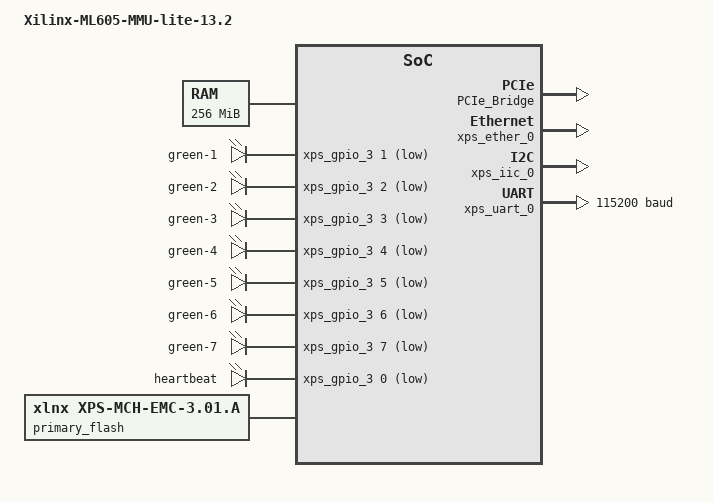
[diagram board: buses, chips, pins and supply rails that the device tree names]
/*
 * Device Tree Generator version: 1.02.a
 *
 * (C) Copyright 2007-2008 Xilinx, Inc.
 *
 * Based on original code:
 * (C) Copyright 2007-2011 PetaLogix Qld Pty Ltd
 *
 * (C) Copyright 2007-2010 Michal Simek
 * Michal SIMEK <monstr@monstr.eu>
 *
 * (C) Copyright 2010-2012 Li-Pro.Net
 * Stephan Linz <linz@li-pro.net>
 *
 * This program is free software; you can redistribute it and/or
 * modify it under the terms of the GNU General Public License as
 * published by the Free Software Foundation; either version 2 of
 * the License, or (at your option) any later version.
 *
 * This program is distributed in the hope that it will be useful,
 * but WITHOUT ANY WARRANTY; without even the implied warranty of
 * MERCHANTABILITY or FITNESS FOR A PARTICULAR PURPOSE. See the
 * GNU General Public License for more details.
 *
 * You should have received a copy of the GNU General Public License
 * along with this program; if not, write to the Free Software
 * Foundation, Inc., 59 Temple Place, Suite 330, Boston,
 * MA 02111-1307 USA
 *
 * CAUTION:  This file is automatically generated by libgen.
 * Version:  Xilinx EDK 13.2 EDK_O.61xd
 * Today is: Montag, the 12 of März, 2012; 08:22:30
 *
 * XPS project directory: Xilinx-ML605-MMU-lite-13.2
 */

/dts-v1/;
/ {
	#address-cells = <1>;
	#size-cells = <1>;
	compatible = "xlnx,microblaze";
	hard-reset-gpios = < &xps_gpio_0 0 1 >;
	model = "Xilinx-ML605-MMU-lite-13.2";
	aliases {
		ethernet0 = &xps_ether_0;
		serial0 = &xps_uart_0;
	} ;
	chosen {
		bootargs = "console=ttyUL0,115200 root=/dev/mtdblock2 rw rootfstype=jffs2 mtdparts=ae000000.flash:16384k(bpi),4096k(kernel),11776k(rootfs),384k(u-boot-xl)ro,128k(env) debug";
		linux,stdout-path = "/plb@0/serial@89ff0000";
	} ;
	cpus {
		#address-cells = <1>;
		#cpus = <0x1>;
		#size-cells = <0>;
		microblaze_0: cpu@0 {
			clock-frequency = <100000000>;
			compatible = "xlnx,microblaze-8.20.a";
			d-cache-baseaddr = <0x20000000>;
			d-cache-highaddr = <0x2fffffff>;
			d-cache-line-size = <0x10>;
			d-cache-size = <0x800>;
			device_type = "cpu";
			i-cache-baseaddr = <0x20000000>;
			i-cache-highaddr = <0x2fffffff>;
			i-cache-line-size = <0x10>;
			i-cache-size = <0x800>;
			model = "microblaze,8.20.a";
			reg = <0>;
			timebase-frequency = <100000000>;
			xlnx,addr-tag-bits = <0x11>;
			xlnx,allow-dcache-wr = <0x1>;
			xlnx,allow-icache-wr = <0x1>;
			xlnx,area-optimized = <0x0>;
			xlnx,avoid-primitives = <0x0>;
			xlnx,branch-target-cache-size = <0x0>;
			xlnx,cache-byte-size = <0x800>;
			xlnx,d-axi = <0x0>;
			xlnx,d-lmb = <0x1>;
			xlnx,d-plb = <0x1>;
			xlnx,data-size = <0x20>;
			xlnx,dcache-addr-tag = <0x11>;
			xlnx,dcache-always-used = <0x1>;
			xlnx,dcache-byte-size = <0x800>;
			xlnx,dcache-data-width = <0x0>;
			xlnx,dcache-force-tag-lutram = <0x0>;
			xlnx,dcache-interface = <0x0>;
			xlnx,dcache-line-len = <0x4>;
			xlnx,dcache-use-fsl = <0x1>;
			xlnx,dcache-use-writeback = <0x0>;
			xlnx,dcache-victims = <0x0>;
			xlnx,debug-enabled = <0x1>;
			xlnx,div-zero-exception = <0x0>;
			xlnx,dynamic-bus-sizing = <0x1>;
			xlnx,ecc-use-ce-exception = <0x0>;
			xlnx,edge-is-positive = <0x1>;
			xlnx,endianness = <0x0>;
			xlnx,family = "virtex6";
			xlnx,fault-tolerant = <0x0>;
			xlnx,fpu-exception = <0x0>;
			xlnx,freq = <0x5f5e100>;
			xlnx,fsl-data-size = <0x20>;
			xlnx,fsl-exception = <0x0>;
			xlnx,fsl-links = <0x0>;
			xlnx,i-axi = <0x0>;
			xlnx,i-lmb = <0x1>;
			xlnx,i-plb = <0x1>;
			xlnx,icache-always-used = <0x1>;
			xlnx,icache-data-width = <0x0>;
			xlnx,icache-force-tag-lutram = <0x0>;
			xlnx,icache-interface = <0x0>;
			xlnx,icache-line-len = <0x4>;
			xlnx,icache-streams = <0x0>;
			xlnx,icache-use-fsl = <0x1>;
			xlnx,icache-victims = <0x0>;
			xlnx,ill-opcode-exception = <0x1>;
			xlnx,instance = "microblaze_0";
			xlnx,interconnect = <0x1>;
			xlnx,interrupt-is-edge = <0x0>;
			xlnx,lockstep-slave = <0x0>;
			xlnx,mmu-dtlb-size = <0x4>;
			xlnx,mmu-itlb-size = <0x2>;
			xlnx,mmu-privileged-instr = <0x0>;
			xlnx,mmu-tlb-access = <0x3>;
			xlnx,mmu-zones = <0x2>;
			xlnx,number-of-pc-brk = <0x1>;
			xlnx,number-of-rd-addr-brk = <0x0>;
			xlnx,number-of-wr-addr-brk = <0x0>;
			xlnx,opcode-0x0-illegal = <0x1>;
			xlnx,optimization = <0x0>;
			xlnx,pvr = <0x2>;
			xlnx,pvr-user1 = <0x0>;
			xlnx,pvr-user2 = <0x0>;
			xlnx,reset-msr = <0x0>;
			xlnx,sco = <0x0>;
			xlnx,stream-interconnect = <0x0>;
			xlnx,unaligned-exceptions = <0x1>;
			xlnx,use-barrel = <0x1>;
			xlnx,use-branch-target-cache = <0x0>;
			xlnx,use-dcache = <0x1>;
			xlnx,use-div = <0x0>;
			xlnx,use-ext-brk = <0x1>;
			xlnx,use-ext-nm-brk = <0x1>;
			xlnx,use-extended-fsl-instr = <0x0>;
			xlnx,use-fpu = <0x0>;
			xlnx,use-hw-mul = <0x1>;
			xlnx,use-icache = <0x1>;
			xlnx,use-interrupt = <0x1>;
			xlnx,use-mmu = <0x3>;
			xlnx,use-msr-instr = <0x1>;
			xlnx,use-pcmp-instr = <0x1>;
			xlnx,use-stack-protection = <0x0>;
		} ;
	} ;
	mpmc_0: memory@20000000 {
		device_type = "memory";
		reg = < 0x20000000 0x10000000 >;
	} ;
	mb_plb: plb@0 {
		#address-cells = <1>;
		#size-cells = <1>;
		compatible = "xlnx,plb-v46-1.05.a", "xlnx,plb-v46-1.00.a", "simple-bus";
		ranges ;
		PCIe_Bridge: plbv46-pcie@8abf0000 {
			compatible = "xlnx,plbv46-pcie-4.07.a";
			interrupt-parent = <&xps_intc_0>;
			interrupts = < 5 2 >;
			reg = < 0x8abf0000 0x10000 >;
			xlnx,board = "none";
			xlnx,class-code = <0x58000>;
			xlnx,comp-timeout = <0x1>;
			xlnx,device = "6vlx240t";
			xlnx,device-id = <0x505>;
			xlnx,family = "virtex6";
			xlnx,include-baroffset-reg = <0x1>;
			xlnx,include-rc = <0x0>;
			xlnx,ipifbar-0 = <0xb0000000>;
			xlnx,ipifbar-1 = <0xe0000000>;
			xlnx,ipifbar-2 = <0xc0000000>;
			xlnx,ipifbar-3 = <0xffffffff>;
			xlnx,ipifbar-4 = <0xffffffff>;
			xlnx,ipifbar-5 = <0xffffffff>;
			xlnx,ipifbar-as-0 = <0x0>;
			xlnx,ipifbar-as-1 = <0x0>;
			xlnx,ipifbar-as-2 = <0x0>;
			xlnx,ipifbar-as-3 = <0x0>;
			xlnx,ipifbar-as-4 = <0x0>;
			xlnx,ipifbar-as-5 = <0x0>;
			xlnx,ipifbar-highaddr-0 = <0xb0ffffff>;
			xlnx,ipifbar-highaddr-1 = <0xffffffff>;
			xlnx,ipifbar-highaddr-2 = <0xcfffffff>;
			xlnx,ipifbar-highaddr-3 = <0x0>;
			xlnx,ipifbar-highaddr-4 = <0x0>;
			xlnx,ipifbar-highaddr-5 = <0x0>;
			xlnx,ipifbar-num = <0x3>;
			xlnx,ipifbar-space-type-0 = <0x1>;
			xlnx,ipifbar-space-type-1 = <0x1>;
			xlnx,ipifbar-space-type-2 = <0x1>;
			xlnx,ipifbar-space-type-3 = <0x1>;
			xlnx,ipifbar-space-type-4 = <0x1>;
			xlnx,ipifbar-space-type-5 = <0x1>;
			xlnx,ipifbar2pcibar-0 = <0x0>;
			xlnx,ipifbar2pcibar-1 = <0x0>;
			xlnx,ipifbar2pcibar-2 = <0xe0000000>;
			xlnx,ipifbar2pcibar-3 = <0xffffffff>;
			xlnx,ipifbar2pcibar-4 = <0xffffffff>;
			xlnx,ipifbar2pcibar-5 = <0xffffffff>;
			xlnx,mplb-awidth = <0x20>;
			xlnx,mplb-dwidth = <0x40>;
			xlnx,mplb-native-dwidth = <0x40>;
			xlnx,mplb-smallest-slave = <0x20>;
			xlnx,no-of-lanes = <0x1>;
			xlnx,pcibar-as = <0x1>;
			xlnx,pcibar-len-0 = <0x1c>;
			xlnx,pcibar-len-1 = <0x10>;
			xlnx,pcibar-len-2 = <0x10>;
			xlnx,pcibar-num = <0x1>;
			xlnx,pcibar2ipifbar-0 = <0xb0000000>;
			xlnx,pcibar2ipifbar-1 = <0xffffffff>;
			xlnx,pcibar2ipifbar-2 = <0xffffffff>;
			xlnx,pcie-cap-slot-implemented = <0x1>;
			xlnx,ref-clk-freq = <0x2>;
			xlnx,rev-id = <0x0>;
			xlnx,subfamily = "lx";
			xlnx,subsystem-id = <0x0>;
			xlnx,subsystem-vendor-id = <0x0>;
			xlnx,vendor-id = <0x10ee>;
		} ;
		gpio-leds {
			compatible = "gpio-leds";
			green-1 {
				gpios = < &xps_gpio_3 1 1 >;
				label = "green-1";
			} ;
			green-2 {
				gpios = < &xps_gpio_3 2 1 >;
				label = "green-2";
			} ;
			green-3 {
				gpios = < &xps_gpio_3 3 1 >;
				label = "green-3";
			} ;
			green-4 {
				gpios = < &xps_gpio_3 4 1 >;
				label = "green-4";
			} ;
			green-5 {
				gpios = < &xps_gpio_3 5 1 >;
				label = "green-5";
			} ;
			green-6 {
				gpios = < &xps_gpio_3 6 1 >;
				label = "green-6";
			} ;
			green-7 {
				gpios = < &xps_gpio_3 7 1 >;
				label = "green-7";
			} ;
			heartbeat {
				gpios = < &xps_gpio_3 0 1 >;
				label = "heartbeat";
				linux,default-trigger = "heartbeat";
			} ;
		} ;
		mbref_mio_0: uio@80400000 {
			compatible = "xlnx,plbv46-mbref-mio-1.00.a", "generic-uio";
			interrupt-parent = <&xps_intc_0>;
			interrupts = < 9 2 >;
			reg = < 0x80400000 0x10000 0x80410000 0x200 0x80411000 0x200 0x80412000 0x200 0x80413000 0x200 >;
			xlnx,family = "virtex6";
			xlnx,include-dphase-timer = <0x1>;
		} ;
		mbref_reg_0: uio@80800000 {
			compatible = "xlnx,plbv46-mbref-reg-1.00.a", "generic-uio";
			interrupt-parent = <&xps_intc_0>;
			interrupts = < 8 2 >;
			reg = < 0x80800000 0x10000 >;
			xlnx,family = "virtex6";
			xlnx,include-dphase-timer = <0x1>;
		} ;
		mdm_0: debug@8fff0000 {
			compatible = "xlnx,mdm-2.00.b", "xlnx,xps-uartlite-1.00.a";
			reg = < 0x8fff0000 0x10000 >;
			xlnx,family = "virtex6";
			xlnx,interconnect = <0x1>;
			xlnx,jtag-chain = <0x2>;
			xlnx,mb-dbg-ports = <0x1>;
			xlnx,use-uart = <0x1>;
		} ;
		mpmc@20000000 {
			#address-cells = <1>;
			#size-cells = <1>;
			compatible = "xlnx,mpmc-6.04.a";
			ranges ;
		} ;
		primary_flash: flash@ae000000 {
			bank-width = <2>;
			compatible = "xlnx,xps-mch-emc-3.01.a", "cfi-flash";
			reg = < 0xae000000 0x2000000 >;
			xlnx,family = "virtex6";
			xlnx,include-datawidth-matching-0 = <0x1>;
			xlnx,include-datawidth-matching-1 = <0x0>;
			xlnx,include-datawidth-matching-2 = <0x0>;
			xlnx,include-datawidth-matching-3 = <0x0>;
			xlnx,include-negedge-ioregs = <0x0>;
			xlnx,include-plb-ipif = <0x1>;
			xlnx,include-wrbuf = <0x1>;
			xlnx,max-mem-width = <0x10>;
			xlnx,mch-native-dwidth = <0x20>;
			xlnx,mch-splb-awidth = <0x20>;
			xlnx,mch-splb-clk-period-ps = <0x2710>;
			xlnx,mch0-accessbuf-depth = <0x10>;
			xlnx,mch0-protocol = <0x0>;
			xlnx,mch0-rddatabuf-depth = <0x10>;
			xlnx,mch1-accessbuf-depth = <0x10>;
			xlnx,mch1-protocol = <0x0>;
			xlnx,mch1-rddatabuf-depth = <0x10>;
			xlnx,mch2-accessbuf-depth = <0x10>;
			xlnx,mch2-protocol = <0x0>;
			xlnx,mch2-rddatabuf-depth = <0x10>;
			xlnx,mch3-accessbuf-depth = <0x10>;
			xlnx,mch3-protocol = <0x0>;
			xlnx,mch3-rddatabuf-depth = <0x10>;
			xlnx,mem0-width = <0x10>;
			xlnx,mem1-width = <0x20>;
			xlnx,mem2-width = <0x20>;
			xlnx,mem3-width = <0x20>;
			xlnx,num-banks-mem = <0x1>;
			xlnx,num-channels = <0x0>;
			xlnx,pagemode-flash-0 = <0x0>;
			xlnx,pagemode-flash-1 = <0x0>;
			xlnx,pagemode-flash-2 = <0x0>;
			xlnx,pagemode-flash-3 = <0x0>;
			xlnx,priority-mode = <0x0>;
			xlnx,synch-mem-0 = <0x0>;
			xlnx,synch-mem-1 = <0x0>;
			xlnx,synch-mem-2 = <0x0>;
			xlnx,synch-mem-3 = <0x0>;
			xlnx,synch-pipedelay-0 = <0x2>;
			xlnx,synch-pipedelay-1 = <0x2>;
			xlnx,synch-pipedelay-2 = <0x2>;
			xlnx,synch-pipedelay-3 = <0x2>;
			xlnx,tavdv-ps-mem-0 = <0x1adb0>;
			xlnx,tavdv-ps-mem-1 = <0x3a98>;
			xlnx,tavdv-ps-mem-2 = <0x3a98>;
			xlnx,tavdv-ps-mem-3 = <0x3a98>;
			xlnx,tcedv-ps-mem-0 = <0x1adb0>;
			xlnx,tcedv-ps-mem-1 = <0x3a98>;
			xlnx,tcedv-ps-mem-2 = <0x3a98>;
			xlnx,tcedv-ps-mem-3 = <0x3a98>;
			xlnx,thzce-ps-mem-0 = <0x88b8>;
			xlnx,thzce-ps-mem-1 = <0x1b58>;
			xlnx,thzce-ps-mem-2 = <0x1b58>;
			xlnx,thzce-ps-mem-3 = <0x1b58>;
			xlnx,thzoe-ps-mem-0 = <0x1b58>;
			xlnx,thzoe-ps-mem-1 = <0x1b58>;
			xlnx,thzoe-ps-mem-2 = <0x1b58>;
			xlnx,thzoe-ps-mem-3 = <0x1b58>;
			xlnx,tlzwe-ps-mem-0 = <0x88b8>;
			xlnx,tlzwe-ps-mem-1 = <0x0>;
			xlnx,tlzwe-ps-mem-2 = <0x0>;
			xlnx,tlzwe-ps-mem-3 = <0x0>;
			xlnx,tpacc-ps-flash-0 = <0x61a8>;
			xlnx,tpacc-ps-flash-1 = <0x61a8>;
			xlnx,tpacc-ps-flash-2 = <0x61a8>;
			xlnx,tpacc-ps-flash-3 = <0x61a8>;
			xlnx,twc-ps-mem-0 = <0x2af8>;
			xlnx,twc-ps-mem-1 = <0x3a98>;
			xlnx,twc-ps-mem-2 = <0x3a98>;
			xlnx,twc-ps-mem-3 = <0x3a98>;
			xlnx,twp-ps-mem-0 = <0x11170>;
			xlnx,twp-ps-mem-1 = <0x2ee0>;
			xlnx,twp-ps-mem-2 = <0x2ee0>;
			xlnx,twp-ps-mem-3 = <0x2ee0>;
			xlnx,xcl0-linesize = <0x4>;
			xlnx,xcl0-writexfer = <0x1>;
			xlnx,xcl1-linesize = <0x4>;
			xlnx,xcl1-writexfer = <0x1>;
			xlnx,xcl2-linesize = <0x4>;
			xlnx,xcl2-writexfer = <0x1>;
			xlnx,xcl3-linesize = <0x4>;
			xlnx,xcl3-writexfer = <0x1>;
		} ;
		xps_central_dma_0: xps-central-dma@8acf0000 {
			compatible = "xlnx,xps-central-dma-2.03.a";
			interrupt-parent = <&xps_intc_0>;
			interrupts = < 1 2 >;
			reg = < 0x8acf0000 0x10000 >;
			xlnx,family = "virtex6";
			xlnx,fifo-depth = <0x8>;
			xlnx,mplb-awidth = <0x20>;
			xlnx,mplb-dwidth = <0x40>;
			xlnx,mplb-native-dwidth = <0x20>;
			xlnx,rd-burst-size = <0x8>;
			xlnx,wr-burst-size = <0x8>;
		} ;
		xps_ether_0: ethernet@88f00000 {
			compatible = "xlnx,xps-ethernetlite-4.00.a", "xlnx,xps-ethernetlite-1.00.a";
			device_type = "network";
			interrupt-parent = <&xps_intc_0>;
			interrupts = < 4 0 >;
			local-mac-address = [ 00 0a 35 00 00 00 ];
			reg = < 0x88f00000 0x10000 >;
			xlnx,duplex = <0x1>;
			xlnx,family = "virtex6";
			xlnx,include-global-buffers = <0x0>;
			xlnx,include-internal-loopback = <0x0>;
			xlnx,include-mdio = <0x1>;
			xlnx,rx-ping-pong = <0x0>;
			xlnx,tx-ping-pong = <0x0>;
		} ;
		xps_gpio_0: gpio@80ff0000 {
			#gpio-cells = <2>;
			compatible = "xlnx,xps-gpio-2.00.a", "xlnx,xps-gpio-1.00.a";
			gpio-controller ;
			reg = < 0x80ff0000 0x10000 >;
			xlnx,all-inputs = <0x0>;
			xlnx,all-inputs-2 = <0x0>;
			xlnx,dout-default = <0x0>;
			xlnx,dout-default-2 = <0x0>;
			xlnx,family = "virtex6";
			xlnx,gpio-width = <0x1>;
			xlnx,gpio2-width = <0x20>;
			xlnx,interrupt-present = <0x0>;
			xlnx,is-dual = <0x0>;
			xlnx,tri-default = <0xffffffff>;
			xlnx,tri-default-2 = <0xffffffff>;
		} ;
		xps_gpio_1: gpio@80fe0000 {
			#gpio-cells = <2>;
			compatible = "xlnx,xps-gpio-2.00.a", "xlnx,xps-gpio-1.00.a";
			gpio-controller ;
			reg = < 0x80fe0000 0x10000 >;
			xlnx,all-inputs = <0x1>;
			xlnx,all-inputs-2 = <0x0>;
			xlnx,dout-default = <0x0>;
			xlnx,dout-default-2 = <0x0>;
			xlnx,family = "virtex6";
			xlnx,gpio-width = <0x5>;
			xlnx,gpio2-width = <0x20>;
			xlnx,interrupt-present = <0x0>;
			xlnx,is-dual = <0x0>;
			xlnx,tri-default = <0xffffffff>;
			xlnx,tri-default-2 = <0xffffffff>;
		} ;
		xps_gpio_2: gpio@80fd0000 {
			#gpio-cells = <2>;
			compatible = "xlnx,xps-gpio-2.00.a", "xlnx,xps-gpio-1.00.a";
			gpio-controller ;
			reg = < 0x80fd0000 0x10000 >;
			xlnx,all-inputs = <0x1>;
			xlnx,all-inputs-2 = <0x0>;
			xlnx,dout-default = <0x0>;
			xlnx,dout-default-2 = <0x0>;
			xlnx,family = "virtex6";
			xlnx,gpio-width = <0x8>;
			xlnx,gpio2-width = <0x20>;
			xlnx,interrupt-present = <0x0>;
			xlnx,is-dual = <0x0>;
			xlnx,tri-default = <0xffffffff>;
			xlnx,tri-default-2 = <0xffffffff>;
		} ;
		xps_gpio_3: gpio@80fc0000 {
			#gpio-cells = <2>;
			compatible = "xlnx,xps-gpio-2.00.a", "xlnx,xps-gpio-1.00.a";
			gpio-controller ;
			reg = < 0x80fc0000 0x10000 >;
			xlnx,all-inputs = <0x0>;
			xlnx,all-inputs-2 = <0x0>;
			xlnx,dout-default = <0x0>;
			xlnx,dout-default-2 = <0x0>;
			xlnx,family = "virtex6";
			xlnx,gpio-width = <0x8>;
			xlnx,gpio2-width = <0x20>;
			xlnx,interrupt-present = <0x0>;
			xlnx,is-dual = <0x0>;
			xlnx,tri-default = <0xffffffff>;
			xlnx,tri-default-2 = <0xffffffff>;
		} ;
		xps_gpio_4: gpio@80fb0000 {
			#gpio-cells = <2>;
			compatible = "xlnx,xps-gpio-2.00.a", "xlnx,xps-gpio-1.00.a";
			gpio-controller ;
			reg = < 0x80fb0000 0x10000 >;
			xlnx,all-inputs = <0x0>;
			xlnx,all-inputs-2 = <0x0>;
			xlnx,dout-default = <0x0>;
			xlnx,dout-default-2 = <0x0>;
			xlnx,family = "virtex6";
			xlnx,gpio-width = <0x5>;
			xlnx,gpio2-width = <0x20>;
			xlnx,interrupt-present = <0x0>;
			xlnx,is-dual = <0x0>;
			xlnx,tri-default = <0xffffffff>;
			xlnx,tri-default-2 = <0xffffffff>;
		} ;
		xps_iic_0: i2c@80ef0000 {
			compatible = "xlnx,xps-iic-2.03.a", "xlnx,xps-iic-2.00.a";
			interrupt-parent = <&xps_intc_0>;
			interrupts = < 7 2 >;
			reg = < 0x80ef0000 0x10000 >;
			xlnx,clk-freq = <0x5f5e100>;
			xlnx,family = "virtex6";
			xlnx,gpo-width = <0x1>;
			xlnx,iic-freq = <0x186a0>;
			xlnx,scl-inertial-delay = <0x5>;
			xlnx,sda-inertial-delay = <0x5>;
			xlnx,ten-bit-adr = <0x0>;
		} ;
		xps_intc_0: interrupt-controller@8aff0000 {
			#interrupt-cells = <0x2>;
			compatible = "xlnx,xps-intc-2.01.a", "xlnx,xps-intc-1.00.a";
			interrupt-controller ;
			reg = < 0x8aff0000 0x10000 >;
			xlnx,kind-of-intr = <0x54>;
			xlnx,num-intr-inputs = <0xa>;
		} ;
		xps_sysace_0: sysace@83600000 {
			8-bit ;
			compatible = "xlnx,xps-sysace-1.01.a", "xlnx,xps-sysace-1.00.a";
			interrupt-parent = <&xps_intc_0>;
			interrupts = < 3 2 >;
			reg = < 0x83600000 0x10000 >;
			xlnx,family = "virtex6";
			xlnx,mem-width = <0x8>;
		} ;
		xps_timer_0: system-timer@8aef0000 {
			compatible = "xlnx,xps-timer-1.02.a", "xlnx,xps-timer-1.00.a";
			interrupt-parent = <&xps_intc_0>;
			interrupts = < 2 0 >;
			reg = < 0x8aef0000 0x10000 >;
			xlnx,count-width = <0x20>;
			xlnx,family = "virtex6";
			xlnx,gen0-assert = <0x1>;
			xlnx,gen1-assert = <0x1>;
			xlnx,one-timer-only = <0x0>;
			xlnx,trig0-assert = <0x1>;
			xlnx,trig1-assert = <0x1>;
		} ;
		xps_uart_0: serial@89ff0000 {
			clock-frequency = <100000000>;
			compatible = "xlnx,xps-uartlite-1.02.a", "xlnx,xps-uartlite-1.00.a";
			current-speed = <115200>;
			device_type = "serial";
			interrupt-parent = <&xps_intc_0>;
			interrupts = < 6 0 >;
			port-number = <0>;
			reg = < 0x89ff0000 0x10000 >;
			xlnx,baudrate = <0x1c200>;
			xlnx,data-bits = <0x8>;
			xlnx,family = "virtex6";
			xlnx,odd-parity = <0x0>;
			xlnx,use-parity = <0x0>;
		} ;
	} ;
} ;
